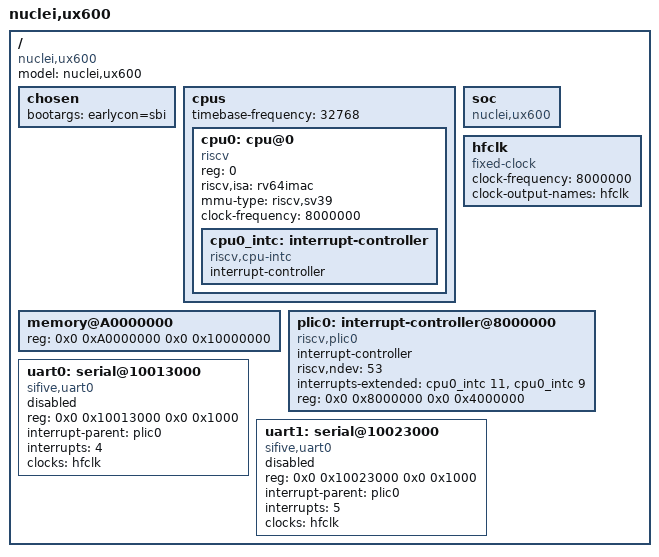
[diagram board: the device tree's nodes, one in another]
/dts-v1/;

/ {
  #address-cells = <2>;
  #size-cells = <2>;
  compatible = "nuclei,ux600";
  model = "nuclei,ux600";
  
  chosen {
     bootargs = "earlycon=sbi";
  };

  cpus {
    #address-cells = <1>;
    #size-cells = <0>;
    timebase-frequency = <32768>;
    cpu0: cpu@0 {
      device_type = "cpu";
      reg = <0>;
      status = "okay";
      compatible = "riscv";
      riscv,isa = "rv64imac";
      mmu-type = "riscv,sv39";
      clock-frequency = <8000000>;
      cpu0_intc: interrupt-controller {
        #interrupt-cells = <1>;
        interrupt-controller;
        compatible = "riscv,cpu-intc";
      };
    };
  };

  memory@A0000000 {
    device_type = "memory";
    reg = <0x0 0xA0000000 0x0 0x10000000>;
  };

  soc {
    #address-cells = <2>;
    #size-cells = <2>;
    compatible = "nuclei,ux600", "simple-bus";
    ranges;
  };

  hfclk: hfclk {
    #clock-cells = <0>;
    compatible = "fixed-clock";
    clock-frequency = <8000000>;
    clock-output-names = "hfclk";
	};
  
  plic0: interrupt-controller@8000000 {
    #interrupt-cells = <1>;
    compatible = "riscv,plic0";
    interrupt-controller;
    riscv,ndev = <53>;
    interrupts-extended =
    	    <&cpu0_intc 11 &cpu0_intc 9>;
    reg = <0x0 0x8000000 0x0 0x4000000>;
	};

	uart0: serial@10013000 {
    compatible = "sifive,uart0";
    reg = <0x0 0x10013000 0x0 0x1000>;
    interrupt-parent = <&plic0>;
    interrupts = <4>;
    clocks = <&hfclk>;
    status = "disabled";
	};

	uart1: serial@10023000 {
    compatible = "sifive,uart0";
    reg = <0x0 0x10023000 0x0 0x1000>;
    interrupt-parent = <&plic0>;
    interrupts = <5>;
    clocks = <&hfclk>;
    status = "disabled";
	};

};
